# RZN2L register map
Vendor: Renesas Electronics Corporation; Series: RZN; File version: 1.30.01
CPU: other r0p0, little endian, MPU, no FPU, VTOR, 4 interrupt priority bits, 624 interrupts
Registers are 32-bit, read-write, reset 0x0 unless marked. A register's access mark holds for its fields unless they carry their own. Offsets are from the block's base; [hi:lo] are bit positions; {n}, {i} and the like mark numbered series.

## ETHSS — Ethernet Subsystem
Base 0x80110000
0x00 PRCMD — Ethernet Protect Register
0x08 MODCTRL — Mode Control Register
  [2:0] SW_MODE — Media I/F connectionSW_MODE[2:0]Media I/FPort 0Port 1Port 2000bETHSW Port 0ETHSW Port 1ETHSW Port 2001bESC Port 0ESC Port 1GMAC Port010bESC Port 0ESC Port 1ETHSW Port 2011bESC Port 0ESC Port 1ESC Port 2100bETHSW Port 0ESC Port 1ESC Port 2101bETHSW Port 0ESC Port 1ETHSW Port 2110b-ETHSW Port 1ETHSW Port 0111b-ESC Port 1ESC Port 0
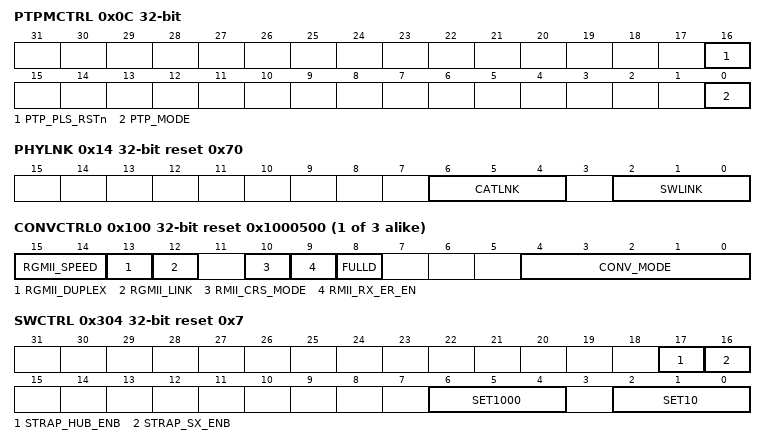
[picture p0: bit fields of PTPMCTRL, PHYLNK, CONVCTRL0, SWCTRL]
0x0C PTPMCTRL — PTP Mode Control Register
  [16] PTP_PLS_RSTn — Reset control for Pulse Generator (unit 0 - 3)
    0=Assert RESET; 1=Release RESET
  [0] PTP_MODE — Select the unit number of PTP Timer for GMAC and Pulse Generator (unit 0 - 3)
    0=Ethernet Switch Timer 0; 1=Ethernet Switch Timer 1
0x14 PHYLNK reset 0x70 — Ethernet PHY Link Mode Register
  [6:4] CATLNK — Specify the active level of the ESC_PHYLINKn signal using the EtherCAT interface
    0=Active-Low PHYLINK signal; 1=Active-High PHYLINK signal
  [2:0] SWLINK — Specify the active level of the ETHSW_PHYLINKn signal using the Ethernet switch interface
    0=Active-High PHYLINK signal; 1=Active-Low PHYLINK signal
{0x100+4i} CONVCTRL{i} (i=0..2) reset 0x1000500 — RGMII/RMII Converter {i} Control Register
  [15:14] RGMII_SPEED ro
    0=2.5 MHz; 1=25 MHz; 2=125 MHz
  [13] RGMII_DUPLEX ro
    0=Half-duplex; 1=Full-duplex
  [12] RGMII_LINK ro
    0=Down; 1=Up
  [10] RMII_CRS_MODE
    0=CRS | TX_EN; 1=CRS | TX_EN | RX_DV
  [9] RMII_RX_ER_EN
    0=RX_ER is always 0; 1=RX_ER signal
  [8] FULLD
    0=Half-duplex; 1=Full-duplex
  [4:0] CONV_MODE — Converter operation mode
0x114 CONVRST — RGMII/RMII Converter Reset Control Register
  [2:0] PHYIR
    0=Reset RGMII/RMII Converter; 1=Activate RGMII/RMII Converter
0x304 SWCTRL reset 0x7 — Switch Core Control Register
  [17] STRAP_HUB_ENB — Initialize switch port 0 and 1 (set during module reset of ETHSW)
    0=Port 0 and 1 stay uninitialized; 1=Port 0 and 1 initialized
  [16] STRAP_SX_ENB — Initialize switch after reset (set during module reset of ETHSW)
    0=Switch stay uninitialized; 1=Switch initialized (line port)
  [6:4] SET1000 — Port control to select use of 1000 Mbps. Bit 0 = port 0, bit 1 = port 1, bit 2 = port 2.
    0=Not 1000 Mbps; 1=1000 Mbps
  [2:0] SET10 — Port control to select use of 10 Mbps. Bit 0 = port 0, bit 1 = port 1, bit 2 = port 2.
    0=Not 10 Mbps; 1=10 Mbps
0x308 SWDUPC — Switch Core Duplex Mode Register
  [2:0] PHY_DUPLEX — Configure the MAC of each port for full-duplex or half-duplex operation. Bit 0 = port 0, bit 1 = port 1, bit 2 = port 2.
    0=Half-duplex; 1=Full-duplex
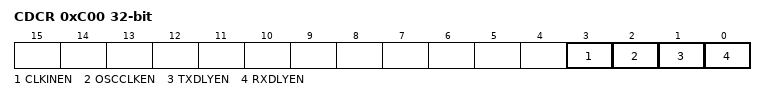
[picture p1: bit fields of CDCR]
0xC00 CDCR — RGMII Clock Delay Control Register
  [all] fields
    0=Disable; 1=Enable
  [3] CLKINEN — Enable Phase shift mode for normal operation
  [2] OSCCLKEN — Enable Oscillation mode for calibration
  [1] TXDLYEN — Enable delay for ETH2_TXCLK
  [0] RXDLYEN — Enable delay for ETH2_RXCLK
0xC10 RXFCNT ro — RGMII RX OSC Frequency Measurement Counter Register
  [15:0] RXFCNT — Oscillation frequency measurement counter for ETH2_RXCLK delay
0xC14 TXFCNT ro — RGMII TX OSC Frequency Measurement Counter Register
  [15:0] TXFCNT — Oscillation frequency measurement counter for ETH2_TXCLK delay
0xC18 RXTAPSEL — RGMII RX TAP Selection Register
  [6:0] RXTAPSEL — TAP selection for ETH2_RXCLK delay (number of taps for 90 degree phase shift)
0xC1C TXTAPSEL — RGMII TX TAP Selection Register
  [6:0] TXTAPSEL — TAP selection for ETH2_TXCLK delay (Number of taps for 90 degree phase shift)
0xC20 MIIMCR — MII Mode Control Register
  [0] MIIM2MEN — Enable MAC-to-MAC MII Mode
    0=Disable; 1=Enable
